# R7FA2A1AB register map
Vendor: Renesas; Series: RA2; File version: 1.1
CPU: CM23 r1p0, little endian, MPU, no FPU, VTOR, 2 interrupt priority bits
Registers are 8-bit, read-write, reset 0x0 unless marked. A register's access mark holds for its fields unless they carry their own. Offsets are from the block's base; [hi:lo] are bit positions; {n}, {i} and the like mark numbered series.

## AGT0 — Asynchronous General purpose Timer 0
Base 0x40084000
Same registers: AGT1 0x40084100
0x00 AGT 16-bit reset 0xFFFF — AGT Counter Register
  [15:0] AGT — 16bit counter and reload registerNOTE : When 1 is written to the TSTOP bit in the AGTCRn register, the 16-bit counter is forcibly stopped and set to FFFFH.
0x02 AGTCMA 16-bit reset 0xFFFF — AGT Compare Match A Register
  [15:0] AGTCMA — AGT Compare Match A RegisterNOTE : When 1 is written to the TSTOP bit in the AGTCRn register, set to FFFFH
0x04 AGTCMB 16-bit reset 0xFFFF — AGT Compare Match B Register
  [15:0] AGTCMB — AGT Compare Match B RegisterNOTE : When 1 is written to the TSTOP bit in the AGTCR register, set to FFFFH
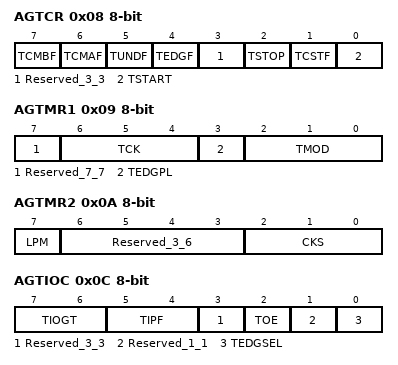
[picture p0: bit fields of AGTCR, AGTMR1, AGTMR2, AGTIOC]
0x08 AGTCR — AGT Control Register
  [7] TCMBF write-0-clears read-modifies — AGT compare match B flag
  [6] TCMAF write-0-clears read-modifies — AGT compare match A flag
  [5] TUNDF write-0-clears read-modifies — AGT underflow flag
  [4] TEDGF write-0-clears read-modifies — Active edge judgement flag
  [3] Reserved_3_3 — This bit is read as 0. The write value should be 0.
  [2] TSTOP wo — AGT count forced stop
  [1] TCSTF ro — AGT count status flag
  [0] TSTART — AGT count start
0x09 AGTMR1 — AGT Mode Register 1
  [7] Reserved_7_7 — This bit is read as 0. The write value should be 0.
  [6:4] TCK — AGT count source select
  [3] TEDGPL — AGTIO edge polarity select
  [2:0] TMOD — AGT operating mode select
0x0A AGTMR2 — AGT Mode Register 2
  [7] LPM — Low Power Mode
  [6:3] Reserved_3_6 — These bits are read as 0000. The write value should be 0000.
  [2:0] CKS — fsub/LOCO count source clock frequency division ratio select
0x0C AGTIOC — AGT I/O Control Register
  [7:6] TIOGT — AGTIO count control
  [5:4] TIPF — AGTIO input filter select
  [3] Reserved_3_3 — This bit is read as 0. The write value should be 0.
  [2] TOE — AGTO output enable
  [1] Reserved_1_1 — This bit is read as 0. The write value should be 0.
  [0] TEDGSEL — I/O polarity switchFunction varies depending on the operating mode.
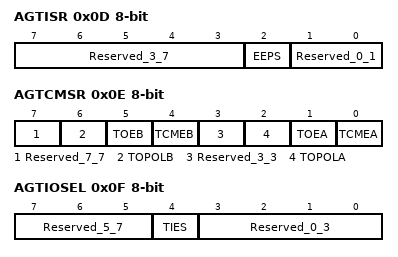
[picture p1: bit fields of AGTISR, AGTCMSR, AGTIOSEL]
0x0D AGTISR — AGT Event Pin Select Register
  [7:3] Reserved_3_7 — These bits are read as 00000. The write value should be 00000.
  [2] EEPS — AGTEE polarty selection
  [1:0] Reserved_0_1 — These bits are read as 00. The write value should be 00.
0x0E AGTCMSR — AGT Compare Match Function Select Register
  [7] Reserved_7_7 — This bit is read as 0. The write value should be 0.
  [6] TOPOLB — AGTOB polarity select
  [5] TOEB — AGTOB output enable
  [4] TCMEB — Compare match B register enable
  [3] Reserved_3_3 — This bit is read as 0. The write value should be 0.
  [2] TOPOLA — AGTOA polarity select
  [1] TOEA — AGTOA output enable
  [0] TCMEA — Compare match A register enable
0x0F AGTIOSEL — AGT Pin Select Register
  [7:5] Reserved_5_7 — These bits are read as 000. The write value should be 000.
  [4] TIES — AGTIO input enable
  [3:0] Reserved_0_3 — These bits are read as 0000. The write value should be 0000.

## GPT_OPS — Output Phase Switching Controller
Base 0x40078FF0
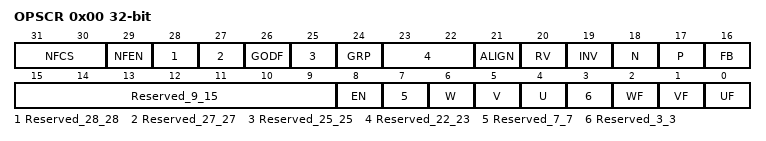
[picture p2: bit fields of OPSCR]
0x00 OPSCR 32-bit — Output Phase Switching Control Register
  [31:30] NFCS — External Input Noise Filter Clock selectionNoise filter sampling clock setting of the external input.
  [29] NFEN — External Input Noise Filter Enable
  [28] Reserved_28_28 — This bit is read as 0. The write value should be 0.
  [27] Reserved_27_27 — This bit is read as 0. The write value should be 0.
  [26] GODF — Group output disable function
  [25] Reserved_25_25 — This bit is read as 0. The write value should be 0.
  [24] GRP — Output disabled source selection
  [23:22] Reserved_22_23 — These bits are read as 00. The write value should be 00.
  [21] ALIGN — Input phase alignment
  [20] RV — Output phase rotation direction reversal
  [19] INV — Invert,Phase Output Control
  [18] N — Negative,Phase Output (N) Control
  [17] P — Positive,Phase Output (P) Control
  [16] FB — External Feedback Signal EnableThis bit selects the input phase from the software settings and external input.
  [15:9] Reserved_9_15 — These bits are read as 0000000. The write value should be 0000000.
  [8] EN — Enable,Phase Output Control
  [7] Reserved_7_7 — This bit is read as 0. The write value should be 0.
  [6] W ro — Input W,Phase MonitorThis bit monitors the state of the input phase.OPSCR.FB=0:External input monitoring by PCLKOPSCR.FB=1:Software settings (UF/VF/WF)
  [5] V ro — Input V,Phase MonitorThis bit monitors the state of the input phase.OPSCR.FB=0:External input monitoring by PCLKOPSCR.FB=1:Software settings (UF/VF/WF)
  [4] U ro — Input U,Phase MonitorThis bit monitors the state of the input phase.OPSCR.FB=0:External input monitoring by PCLKOPSCR.FB=1:Software settings (UF/VF/WF)
  [3] Reserved_3_3 — This bit is read as 0. The write value should be 0.
  [2] WF — Input Phase Soft Setting UFThis bit sets the input phase by the software settings.This bit setting is valid when the OPSCR.FB bit = 1.
  [1] VF — Input Phase Soft Setting VFThis bit sets the input phase by the software settings.This bit setting is valid when the OPSCR.FB bit = 1.
  [0] UF — Input Phase Soft Setting WFThis bit sets the input phase by the software settings.This bit setting is valid when the OPSCR.FB bit = 1.

## POEG — Port Output Enable Module for GPT
Base 0x40042000
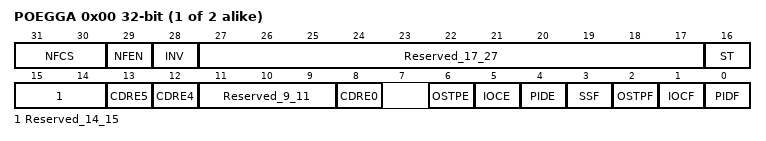
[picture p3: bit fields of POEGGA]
0x00 POEGG{x} (x=A,B; step 0x100) 32-bit — POEG Group {x} Setting Register
  [31:30] NFCS — Noise Filter Clock Select
  [29] NFEN — Noise Filter Enable
  [28] INV — GTETRG Input Reverse
  [27:17] Reserved_17_27 — These bits are read as 00000000000. The write value should be 00000000000.
  [16] ST ro — GTETRG Input Status Flag
  [15:14] Reserved_14_15 — These bits are read as 00. The write value should be 00.
  [13] CDRE5 — ACMP_LP1 EnableNote: Can be modified only once after a reset.
  [12] CDRE4 — ACMP_LP0 EnableNote: Can be modified only once after a reset.
  [11:9] Reserved_9_11 — These bits are read as 000. The write value should be 000.
  [8] CDRE0 — ACMP_HS0 EnableNote: Can be modified only once after a reset.
  [6] OSTPE — Oscillation Stop Detection EnableNote: Can be modified only once after a reset.
  [5] IOCE — Real Time Overcurrent EnableNote: Can be modified only once after a reset.
  [4] PIDE — Port Input Detection EnableNote: Can be modified only once after a reset.
  [3] SSF — Software Stop Flag
  [2] OSTPF write-0-clears read-modifies — Oscillation Stop Detection Flag
  [1] IOCF write-0-clears read-modifies — Real Time Overcurrent Detection Flag
  [0] PIDF write-0-clears read-modifies — Port Input Detection Flag

## FCACHE — Flash Cache
Base 0x4001C000
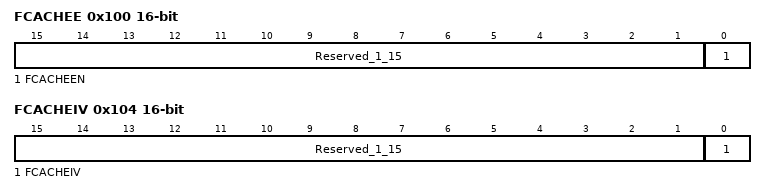
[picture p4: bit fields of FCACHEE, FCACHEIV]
0x100 FCACHEE 16-bit — Flash Cache Enable Register
  [15:1] Reserved_1_15 — These bits are read as 000000000000000. The write value should be 000000000000000.
  [0] FCACHEEN — FCACHE Enable
0x104 FCACHEIV 16-bit — Flash Cache Invalidate Register
  [15:1] Reserved_1_15 — These bits are read as 000000000000000. The write value should be 000000000000000.
  [0] FCACHEIV write-1-sets read-modifies — FCACHE Invalidation

## PORT0 — Port 0 Control Registers
Base 0x40040000
Same registers: PORT3 0x40040060, PORT4 0x40040080, PORT5 0x400400A0, PORT9 0x40040120
0x00 PCNTR1 32-bit — Port Control Register 1
0x00 PODR 16-bit (alternate view of PCNTR1) — Output data register
0x02 PDR 16-bit (alternate view of PCNTR1) — Direction register
0x04 PCNTR2 32-bit ro (reset mask 0xFFFF0000) — Port Control Register 2
0x06 PIDR 16-bit ro reset not defined (alternate view of PCNTR2) — Input data register
0x08 PCNTR3 32-bit wo — Port Control Register 3
0x08 PORR 16-bit wo (alternate view of PCNTR3) — Output reset register
0x0A POSR 16-bit wo (alternate view of PCNTR3) — Output set register

## PORT1 — Port 1 Control Registers
Base 0x40040020
Same registers: PORT2 0x40040040
Registers as PORT0; these are added or differ:
0x04 EIDR 16-bit ro (alternate view of PCNTR2) — Event input data register
0x0C PCNTR4 32-bit — Port Control Register 4
0x0C EORR 16-bit (alternate view of PCNTR4) — Event output reset register
0x0E EOSR 16-bit (alternate view of PCNTR4) — Event output set register

## PMISC — Miscellaneous Port Control Register
Base 0x40040D00
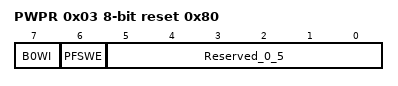
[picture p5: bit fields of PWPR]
0x03 PWPR reset 0x80 — Write,Protect Register
  [7] B0WI — PFSWE Bit Write Disable
  [6] PFSWE — PFS Register Write Enable
  [5:0] Reserved_0_5 — These bits are read as 000000. The write value should be 000000.
